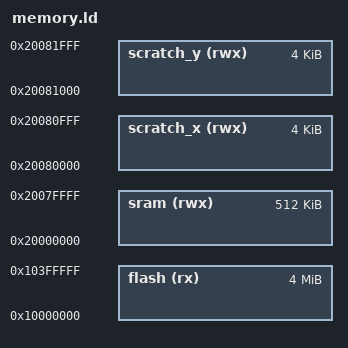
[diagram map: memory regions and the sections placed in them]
/* SPDX-License-Identifier: Apache-2.0 */
/* Generated by tools/memgen from memory.toml: do not edit.
   Raspberry Pi Pico 2 W: RP2350, 4 MB QSPI flash */
MEMORY
{
  flash (rx) : ORIGIN = 0x10000000, LENGTH = 4M
  sram (rwx) : ORIGIN = 0x20000000, LENGTH = 512K
  scratch_x (rwx) : ORIGIN = 0x20080000, LENGTH = 4K
  scratch_y (rwx) : ORIGIN = 0x20081000, LENGTH = 4K
}

REGION_ALIAS("stack", scratch_y);
__keel_stack_size = 4K;
